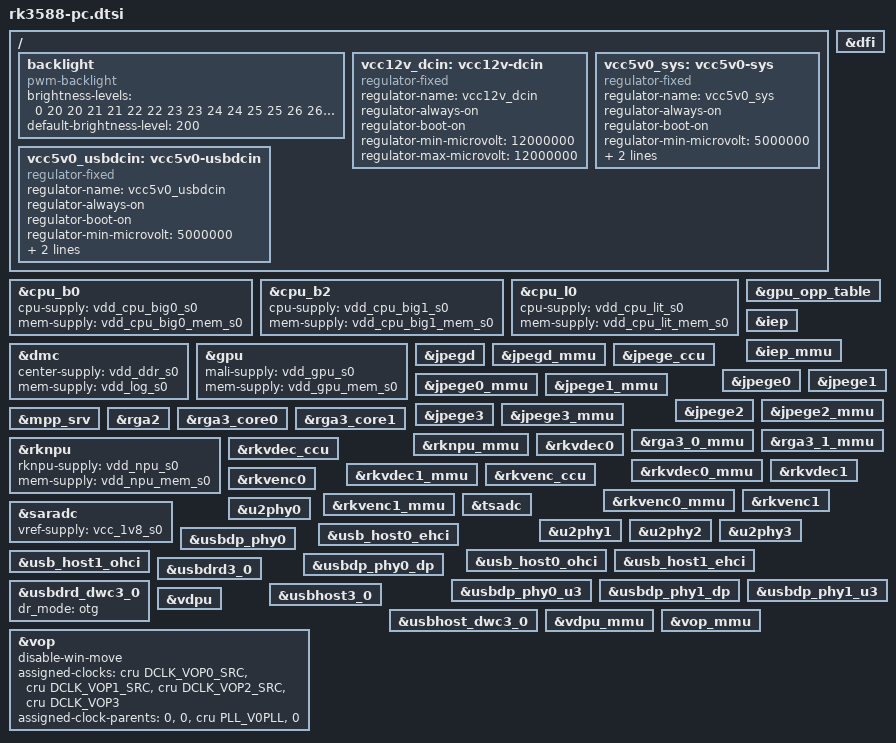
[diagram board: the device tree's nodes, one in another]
// SPDX-License-Identifier: (GPL-2.0+ OR MIT)
/*
 * Copyright (c) 2021 Rockchip Electronics Co., Ltd.
 *
 */

#include <dt-bindings/display/rockchip_vop.h>

/ {

	backlight: backlight {
		compatible = "pwm-backlight";
		brightness-levels = <
			  0  20  20  21  21  22  22  23
			 23  24  24  25  25  26  26  27
			 27  28  28  29  29  30  30  31
			 31  32  32  33  33  34  34  35
			 35  36  36  37  37  38  38  39
			 40  41  42  43  44  45  46  47
			 48  49  50  51  52  53  54  55
			 56  57  58  59  60  61  62  63
			 64  65  66  67  68  69  70  71
			 72  73  74  75  76  77  78  79
			 80  81  82  83  84  85  86  87
			 88  89  90  91  92  93  94  95
			 96  97  98  99 100 101 102 103
			104 105 106 107 108 109 110 111
			112 113 114 115 116 117 118 119
			120 121 122 123 124 125 126 127
			128 129 130 131 132 133 134 135
			136 137 138 139 140 141 142 143
			144 145 146 147 148 149 150 151
			152 153 154 155 156 157 158 159
			160 161 162 163 164 165 166 167
			168 169 170 171 172 173 174 175
			176 177 178 179 180 181 182 183
			184 185 186 187 188 189 190 191
			192 193 194 195 196 197 198 199
			200 201 202 203 204 205 206 207
			208 209 210 211 212 213 214 215
			216 217 218 219 220 221 222 223
			224 225 226 227 228 229 230 231
			232 233 234 235 236 237 238 239
			240 241 242 243 244 245 246 247
			248 249 250 251 252 253 254 255
		>;
		default-brightness-level = <200>;
	};

	vcc12v_dcin: vcc12v-dcin {
		compatible = "regulator-fixed";
		regulator-name = "vcc12v_dcin";
		regulator-always-on;
		regulator-boot-on;
		regulator-min-microvolt = <12000000>;
		regulator-max-microvolt = <12000000>;
	};

	vcc5v0_sys: vcc5v0-sys {
		compatible = "regulator-fixed";
		regulator-name = "vcc5v0_sys";
		regulator-always-on;
		regulator-boot-on;
		regulator-min-microvolt = <5000000>;
		regulator-max-microvolt = <5000000>;
		vin-supply = <&vcc12v_dcin>;
	};

	vcc5v0_usbdcin: vcc5v0-usbdcin {
		compatible = "regulator-fixed";
		regulator-name = "vcc5v0_usbdcin";
		regulator-always-on;
		regulator-boot-on;
		regulator-min-microvolt = <5000000>;
		regulator-max-microvolt = <5000000>;
		vin-supply = <&vcc12v_dcin>;
	};
};

&cpu_b0 {
	cpu-supply = <&vdd_cpu_big0_s0>;
	mem-supply = <&vdd_cpu_big0_mem_s0>;
};

&cpu_b2 {
	cpu-supply = <&vdd_cpu_big1_s0>;
	mem-supply = <&vdd_cpu_big1_mem_s0>;
};

&cpu_l0 {
	cpu-supply = <&vdd_cpu_lit_s0>;
	mem-supply = <&vdd_cpu_lit_mem_s0>;
};

&dfi {
	status = "okay";
};

&dmc {
	center-supply = <&vdd_ddr_s0>;
	mem-supply = <&vdd_log_s0>;
	status = "okay";
};

&gpu {
	mali-supply = <&vdd_gpu_s0>;
	mem-supply = <&vdd_gpu_mem_s0>;
	status = "okay";
};

&gpu_opp_table {
	/delete-node/ opp-198000000;
	/delete-node/ opp-297000000;
	/delete-node/ opp-396000000;
	/delete-node/ opp-594000000;
};

&iep {
	status = "okay";
};

&iep_mmu {
	status = "okay";
};

&jpegd {
	status = "okay";
};

&jpegd_mmu {
	status = "okay";
};

&jpege_ccu {
	status = "okay";
};

&jpege0 {
	status = "okay";
};

&jpege0_mmu {
	status = "okay";
};

&jpege1 {
	status = "okay";
};

&jpege1_mmu {
	status = "okay";
};

&jpege2 {
	status = "okay";
};

&jpege2_mmu {
	status = "okay";
};

&jpege3 {
	status = "okay";
};

&jpege3_mmu {
	status = "okay";
};

&mpp_srv {
	status = "okay";
};

&rga2 {
	status = "okay";
};

&rga3_core0 {
	status = "okay";
};

&rga3_0_mmu {
	status = "okay";
};

&rga3_core1 {
	status = "okay";
};

&rga3_1_mmu {
	status = "okay";
};

&rknpu {
	rknpu-supply = <&vdd_npu_s0>;
	mem-supply = <&vdd_npu_mem_s0>;
	status = "okay";
};

&rknpu_mmu {
	status = "okay";
};

&rkvdec_ccu {
	status = "okay";
};

&rkvdec0 {
	status = "okay";
};

&rkvdec0_mmu {
	status = "okay";
};

&rkvdec1 {
	status = "okay";
};

&rkvdec1_mmu {
	status = "okay";
};

&rkvenc_ccu {
	status = "okay";
};

&rkvenc0 {
	status = "okay";
};

&rkvenc0_mmu {
	status = "okay";
};

&rkvenc1 {
	status = "okay";
};

&rkvenc1_mmu {
	status = "okay";
};

&saradc {
	status = "okay";
	vref-supply = <&vcc_1v8_s0>;
};

&tsadc {
	status = "okay";
};

&u2phy0 {
	status = "okay";
};

&u2phy1 {
	status = "okay";
};

&u2phy2 {
	status = "okay";
};

&u2phy3 {
	status = "okay";
};


&usb_host0_ehci {
	status = "okay";
};

&usb_host0_ohci {
	status = "okay";
};

&usb_host1_ehci {
	status = "okay";
};

&usb_host1_ohci {
	status = "okay";
};

&usbdp_phy0 {
	status = "okay";
};

&usbdp_phy0_dp {
	status = "okay";
};

&usbdp_phy0_u3 {
	status = "okay";
};

&usbdp_phy1_dp {
	status = "okay";
};

&usbdp_phy1_u3 {
	status = "okay";
};

&usbdrd3_0 {
	status = "okay";
};

&usbdrd_dwc3_0 {
	dr_mode = "otg";
	status = "okay";
};

&usbhost3_0 {
	status = "okay";
};

&usbhost_dwc3_0 {
	status = "okay";
};

&vdpu {
	status = "okay";
};

&vdpu_mmu {
	status = "okay";
};

&vop {
	disable-win-move;
	assigned-clocks = <&cru DCLK_VOP0_SRC>,
			  <&cru DCLK_VOP1_SRC>,
			  <&cru DCLK_VOP2_SRC>,
			  <&cru DCLK_VOP3>;
	assigned-clock-parents = <0>, <0>, <&cru PLL_V0PLL>, <0>;
	status = "okay";
};

&vop_mmu {
	status = "okay";
};
